# MKL28T7_CORE0 register map
Vendor: Freescale Semiconductor, Inc.; Series: Kinetis_L; File version: 1.6
CPU: CM0PLUS r0p0, little endian, no MPU, no FPU, VTOR, 2 interrupt priority bits
Registers are 32-bit, read-write, reset 0x0 unless marked. A register's access mark holds for its fields unless they carry their own. Offsets are from the block's base; [hi:lo] are bit positions; {n}, {i} and the like mark numbered series; 'fields as' and 'values as' point back to an identical list.

## SMC — System Mode Controller
Base 0x4007E000; register names take the prefix SMC_
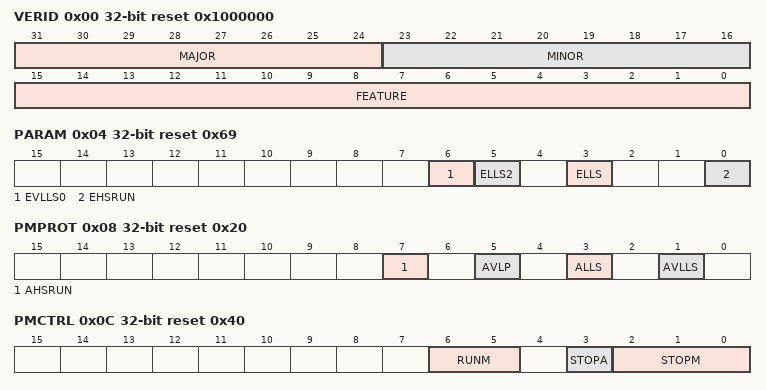
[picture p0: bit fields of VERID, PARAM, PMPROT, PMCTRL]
0x00 VERID ro reset 0x1000000 — SMC Version ID Register
  [31:24] MAJOR — Major Version Number
  [23:16] MINOR — Minor Version Number
  [15:0] FEATURE — Feature Specification Number
    0=Standard features implemented
0x04 PARAM ro reset 0x69 — SMC Parameter Register
  [6] EVLLS0 — Enable VLLS0 (if this mode exists on the SOC)
  [5] ELLS2 — Enable LLS2 (if this mode exists on the SOC)
  [3] ELLS — Enable LLS (if this mode exists on the SOC)
  [0] EHSRUN — Enable HSRUN
0x08 PMPROT reset 0x20 — Power Mode Protection register
  [7] AHSRUN — Allow High Speed Run mode
    0=HSRUN is not allowed; 1=HSRUN is allowed
  [5] AVLP — Allow Very-Low-Power Modes
    0=VLPR, VLPW, and VLPS are not allowed; 1=VLPR, VLPW, and VLPS are allowed
  [3] ALLS — Allow Low-Leakage Stop Mode
    0=Any LLSx mode is not allowed; 1=Any LLSx mode is allowed
  [1] AVLLS — Allow Very-Low-Leakage Stop Mode
    0=Any VLLSx mode is not allowed; 1=Any VLLSx mode is allowed
0x0C PMCTRL reset 0x40 — Power Mode Control register
  [6:5] RUNM — Run Mode Control
    0=Normal Run mode (RUN); 2=Very-Low-Power Run mode (VLPR); 3=High Speed Run mode (HSRUN)
  [3] STOPA ro — Stop Aborted
    0=The previous stop mode entry was successsful; 1=The previous stop mode entry was aborted
  [2:0] STOPM — Stop Mode Control
    0=Normal Stop (STOP); 2=Very-Low-Power Stop (VLPS); 3=Low-Leakage Stop (LLSx); 4=Very-Low-Leakage Stop (VLLSx); 6=Reseved
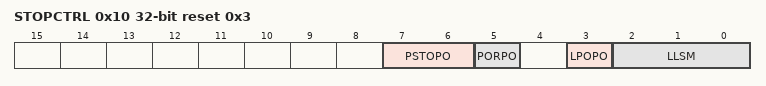
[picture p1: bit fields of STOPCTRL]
0x10 STOPCTRL reset 0x3 — Stop Control Register
  [7:6] PSTOPO — Partial Stop Option
    0=STOP - Normal Stop mode; 1=PSTOP1 - Partial Stop with both system and bus clocks disabled; 2=PSTOP2 - Partial Stop with system clock disabled and bus clock enabled
  [5] PORPO — POR Power Option
    0=POR detect circuit is enabled in VLLS0; 1=POR detect circuit is disabled in VLLS0
  [3] LPOPO — LPO Power Option
    0=LPO clock is enabled in LLS/VLLSx; 1=LPO clock is disabled in LLS/VLLSx
  [2:0] LLSM — LLS or VLLS Mode Control
    0=VLLS0 if PMCTRL[STOPM]=VLLSx, reserved if PMCTRL[STOPM]=LLSx; 1=VLLS1 if PMCTRL[STOPM]=VLLSx, reserved if PMCTRL[STOPM]=LLSx; 2=VLLS2 if PMCTRL[STOPM]=VLLSx, LLS2 if PMCTRL[STOPM]=LLSx; 3=VLLS3 if PMCTRL[STOPM]=VLLSx, LLS3 if PMCTRL[STOPM]=LLSx
0x14 PMSTAT ro reset 0x4 — Power Mode Status register
  [7:0] PMSTAT — Power Mode Status

## TRGMUX1
Base 0x400A7000
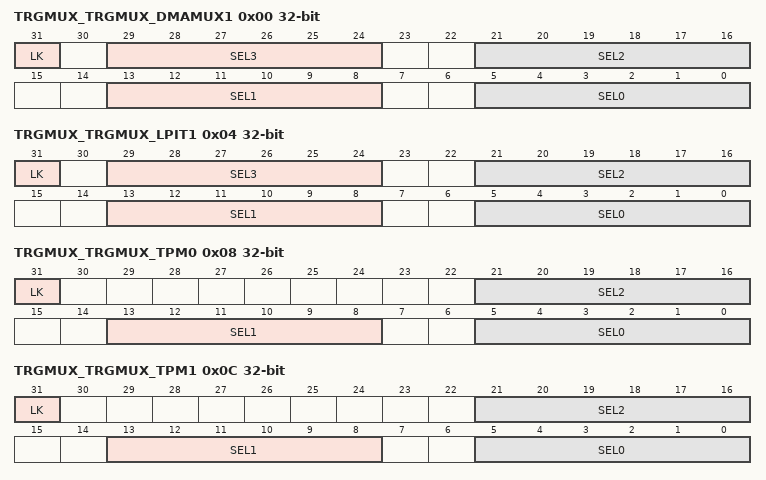
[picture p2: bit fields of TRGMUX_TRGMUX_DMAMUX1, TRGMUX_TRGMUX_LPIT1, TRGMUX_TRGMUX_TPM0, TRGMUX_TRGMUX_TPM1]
0x00 TRGMUX_TRGMUX_DMAMUX1 — TRGMUX TRGCFG Register
  [31] LK — Enable
    0=Register can be written; 1=Register cannot be written until the next system Reset
  [8n+5:8n] SEL{n} (n=0..3) — Trigger MUX Input {n} Source Select
0x04 TRGMUX_TRGMUX_LPIT1 — TRGMUX TRGCFG Register
  fields as TRGMUX_TRGMUX_DMAMUX1
0x08 TRGMUX_TRGMUX_TPM0 — TRGMUX TRGCFG Register
  [31] LK — Enable
    values as TRGMUX_TRGMUX_DMAMUX1.LK
  [21:16] SEL2 — Trigger MUX Input 2 Source Select
  [13:8] SEL1 — Trigger MUX Input 1 Source Select
  [5:0] SEL0 — Trigger MUX Input 0 Source Select
0x0C TRGMUX_TRGMUX_TPM1 — TRGMUX TRGCFG Register
  fields as TRGMUX_TRGMUX_TPM0
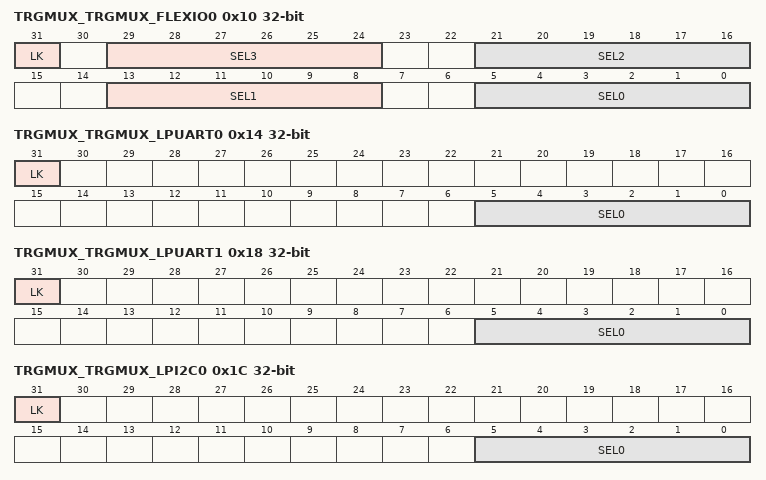
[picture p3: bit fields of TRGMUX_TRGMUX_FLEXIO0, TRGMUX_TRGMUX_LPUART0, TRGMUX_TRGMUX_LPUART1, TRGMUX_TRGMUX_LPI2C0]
0x10 TRGMUX_TRGMUX_FLEXIO0 — TRGMUX TRGCFG Register
  fields as TRGMUX_TRGMUX_DMAMUX1
0x14 TRGMUX_TRGMUX_LPUART0 — TRGMUX TRGCFG Register
  [31] LK — Enable
    values as TRGMUX_TRGMUX_DMAMUX1.LK
  [5:0] SEL0 — Trigger MUX Input 0 Source Select
0x18 TRGMUX_TRGMUX_LPUART1 — TRGMUX TRGCFG Register
  fields as TRGMUX_TRGMUX_LPUART0
0x1C TRGMUX_TRGMUX_LPI2C0 — TRGMUX TRGCFG Register
  fields as TRGMUX_TRGMUX_LPUART0
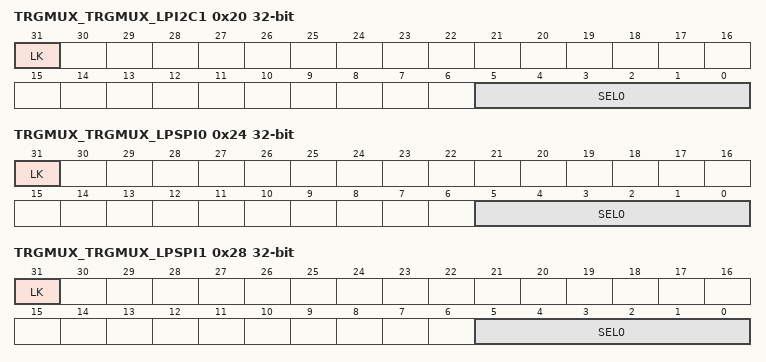
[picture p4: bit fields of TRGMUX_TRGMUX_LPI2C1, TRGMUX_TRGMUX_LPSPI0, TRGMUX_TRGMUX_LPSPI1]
0x20 TRGMUX_TRGMUX_LPI2C1 — TRGMUX TRGCFG Register
  fields as TRGMUX_TRGMUX_LPUART0
0x24 TRGMUX_TRGMUX_LPSPI0 — TRGMUX TRGCFG Register
  fields as TRGMUX_TRGMUX_LPUART0
0x28 TRGMUX_TRGMUX_LPSPI1 — TRGMUX TRGCFG Register
  fields as TRGMUX_TRGMUX_LPUART0
